# A64 register map
Vendor: Allwinner; Series: A64; File version: 0.1
CPU: CA53 0, little endian, MPU, no FPU, 0 interrupt priority bits
Registers are 32-bit, read-write, reset 0x0 unless marked. A register's access mark holds for its fields unless they carry their own. Offsets are from the block's base; [hi:lo] are bit positions; {n}, {i} and the like mark numbered series; 'fields as' and 'values as' point back to an identical list.

## PIO
Base 0x01C20800
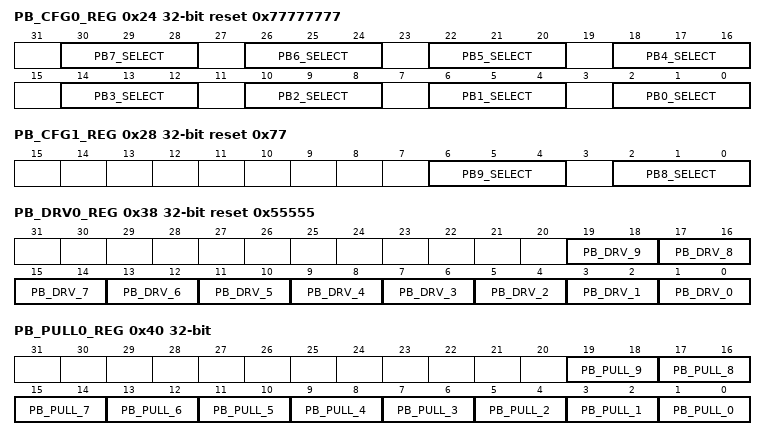
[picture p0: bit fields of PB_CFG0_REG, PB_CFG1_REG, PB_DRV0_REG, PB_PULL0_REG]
0x24 PB_CFG0_REG reset 0x77777777
  [30:28] PB7_SELECT — 000: Input 001: Output 010: AIF2_DIN 011: PCM0_DIN 100: Reserved 101: SIM_DET 110: PB_EINT7 111: IO Disable
    0=Input; 1=Output; 2=AIF2_DIN; 3=PCM0_DIN; 5=SIM_DET; 6=PB_EINT7; 7=IO (IO Disable)
  [26:24] PB6_SELECT — 000: Input 001: Output 010: AIF2_DOUT 011: PCM0_DOUT 100: Reserved 101: SIM_RST 110: PB_EINT6 111: IO Disable
    0=Input; 1=Output; 2=AIF2_DOUT; 3=PCM0_DOUT; 5=SIM_RST; 6=PB_EINT6; 7=IO (IO Disable)
  [22:20] PB5_SELECT — 000: Input 001: Output 010: AIF2_BCLK 011: PCM0_BCLK 100: Reserved 101: SIM_DATA 110: PB_EINT5 111: IO Disable
    0=Input; 1=Output; 2=AIF2_BCLK; 3=PCM0_BCLK; 5=SIM_DATA; 6=PB_EINT5; 7=IO (IO Disable)
  [18:16] PB4_SELECT — 000: Input 001: Output 010: AIF2_SYNC 011: PCM0_SYNC 100: Reserved 101: SIM_CLK 110: PB_EINT4 111: IO Disable
    0=Input; 1=Output; 2=AIF2_SYNC; 3=PCM0_SYNC; 5=SIM_CLK; 6=PB_EINT4; 7=IO (IO Disable)
  [14:12] PB3_SELECT — 000: Input 001: Output 010: UART2_CTS 011: I2S0_MCLK 100: JTAG_DI0 101: SIM_VPPPP 110: PB_EINT3 111: IO Disable
    0=Input; 1=Output; 2=UART2_CTS; 3=I2S0_MCLK; 4=JTAG_DI0; 5=SIM_VPPPP; 6=PB_EINT3; 7=IO (IO Disable)
  [10:8] PB2_SELECT — 000: Input 001: Output 010: UART2_RTS 011: Reserved 100: JTAG_DO0 101: SIM_VPPEN 110: PB_EINT2 111: IO Disable
    0=Input; 1=Output; 2=UART2_RTS; 4=JTAG_DO0; 5=SIM_VPPEN; 6=PB_EINT2; 7=IO (IO Disable)
  [6:4] PB1_SELECT — 000: Input 001: Output 010: UART2_RX 011: Reserved 100: JTAG_CK0 101: SIM_PWREN 110: PB_EINT1 111: IO Disable
    0=Input; 1=Output; 2=UART2_RX; 4=JTAG_CK0; 5=SIM_PWREN; 6=PB_EINT1; 7=IO (IO Disable)
  [2:0] PB0_SELECT — 000: Input 001: Output 010: UART2_TX 011: Reserved 100: JTAG_MS0 101: Reserved 110: PB_EINT0 111: IO Disable
    0=Input; 1=Output; 2=UART2_TX; 4=JTAG_MS0; 6=PB_EINT0; 7=IO (IO Disable)
0x28 PB_CFG1_REG reset 0x77
  [6:4] PB9_SELECT — 000: Input 001: Output 010: Reserved 011: Reserved 100: UART0_RX 101: Reserved 110: PB_EINT9 111: IO Disable
    0=Input; 1=Output; 4=UART0_RX; 6=PB_EINT9; 7=IO (IO Disable)
  [2:0] PB8_SELECT — 000: Input 001: Output 010: Reserved 011: Reserved 100: UART0_TX 101: Reserved 110: PB_EINT8 111: IO Disable
    0=Input; 1=Output; 4=UART0_TX; 6=PB_EINT8; 7=IO (IO Disable)
0x2C PB_CFG2_REG reset not defined
0x30 PB_CFG3_REG reset not defined
0x34 PB_DATA_REG
  [9:0] PB_DAT — If the port is configured as input, the corresponding bit is the pin state. If the port is configured as output, the pin state is the same as the corresponding bit. The read bit value is the value setup by software. If the port is configured as functional pin, the undefined value will be read.
0x38 PB_DRV0_REG reset 0x55555
  [2n+1:2n] PB_DRV_{n} (n=0..9) — PB[n] Multi-Driving Select (n = 0~9) 00: Level 0 01: Level 1 10: Level 2 11: Level 3
0x3C PB_DRV1_REG reset not defined
0x40 PB_PULL0_REG
  [2n+1:2n] PB_PULL_{n} (n=0..9) — PB[n] Pull-up/down Select (n = 0~9) 00: Pull-up/down disable 01: Pull-up 10: Pull-down 11: Reserved
0x44 PB_PULL1_REG reset not defined
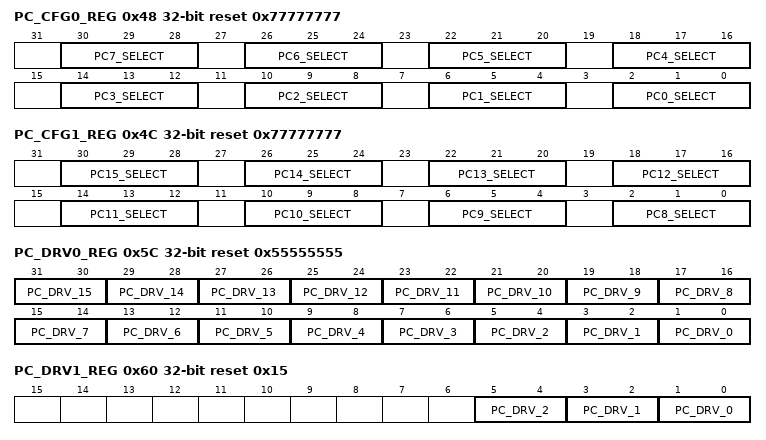
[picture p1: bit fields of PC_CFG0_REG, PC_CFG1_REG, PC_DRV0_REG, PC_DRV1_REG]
0x48 PC_CFG0_REG reset 0x77777777
  [30:28] PC7_SELECT — 000: Input 001: Output 010: NAND_RB1 011: Reserved 100: Reserved 101: Reserved 110: Reserved 111: IO Disable
    0=Input; 1=Output; 2=NAND_RB1; 7=IO (IO Disable)
  [26:24] PC6_SELECT — 000: Input 001: Output 010: NAND_RB0 011: SDC2_CMD 100: Reserved 101: Reserved 110: Reserved 111: IO Disable
    0=Input; 1=Output; 2=NAND_RB0; 3=SDC2_CMD; 7=IO (IO Disable)
  [22:20] PC5_SELECT — 000: Input 001: Output 010: NAND_RE 011: SDC2_CLK 100: Reserved 101: Reserved 110: Reserved 111: IO Disable
    0=Input; 1=Output; 2=NAND_RE; 3=SDC2_CLK; 7=IO (IO Disable)
  [18:16] PC4_SELECT — 000: Input 001: Output 010: NAND_CE0 011: Reserved 100: Reserved 101: Reserved 110: Reserved 111: IO Disable
    0=Input; 1=Output; 2=NAND_CE0; 7=IO (IO Disable)
  [14:12] PC3_SELECT — 000: Input 001: Output 010: NAND_CE1 011: Reserved 100: SPI0_CS 101: Reserved 110: Reserved 111: IO Disable
    0=Input; 1=Output; 2=NAND_CE1; 4=SPI0_CS; 7=IO (IO Disable)
  [10:8] PC2_SELECT — 000: Input 001: Output 010: NAND_CLE 011: Reserved 100: SPI0_CLK 101: Reserved 110: Reserved 111: IO Disable
    0=Input; 1=Output; 2=NAND_CLE; 4=SPI0_CLK; 7=IO (IO Disable)
  [6:4] PC1_SELECT — 000: Input 001: Output 010: NAND_ALE 011: SDC2_DS 100: SPI0_MISO 101: Reserved 110: Reserved 111: IO Disable
    0=Input; 1=Output; 2=NAND_ALE; 3=SDC2_DS; 4=SPI0_MISO; 7=IO (IO Disable)
  [2:0] PC0_SELECT — 000: Input 001: Output 010: NAND_WE 011: Reserved 100: SPI0_MOSI 101: Reserved 110: Reserved 111: IO Disable
    0=Input; 1=Output; 2=NAND_WE; 4=SPI0_MOSI; 7=IO (IO Disable)
0x4C PC_CFG1_REG reset 0x77777777
  [4n-30:4n-32] PC{n}_SELECT (n=8..15) — 000:Input 001:Output 010:NAND_DQ{n-8} 011:SDC2_D{n-8} 100:Reserved 101:Reserved 110:Reserved 111:IO Disable
0x50 PC_CFG2_REG reset 0x777
  [2:0] PC16_SELECT — 000:Input 001:Output 010:NAND_DQS 011:SDC2_RST 100:Reserved 101:Reserved 110:Reserved 111:IO Disable
0x54 PC_CFG3_REG reset not defined
0x58 PC_DATA_REG
  [18:0] PC_DAT — If the port is configured as input, the corresponding bit is the pin state. If the port is configured as output, the pin state is the same as the corresponding bit. The read bit value is the value setup by software. If the port is configured as functional pin, the undefined value will be read.
0x5C PC_DRV0_REG reset 0x55555555
  [2n+1:2n] PC_DRV_{n} (n=0..15) — PC[n] Multi-Driving SELECT (n = 0~15) 00: Level 0 01: Level 1 10: Level 2 11: Level 3
0x60 PC_DRV1_REG reset 0x15
  [5:4] PC_DRV_2 — PC[n] Multi-Driving Select (n = 16~18) 00: Level 0 01: Level 1 10: Level 2 11: Level 3
  [3:2] PC_DRV_1 — PC[n] Multi-Driving Select (n = 16~18) 00: Level 0 01: Level 1 10: Level 2 11: Level 3
  [1:0] PC_DRV_0 — PC[n] Multi-Driving Select (n = 16~18) 00: Level 0 01: Level 1 10: Level 2 11: Level 3
0x64 PC_PULL0_REG reset not defined
0x68 PC_PULL1_REG reset not defined
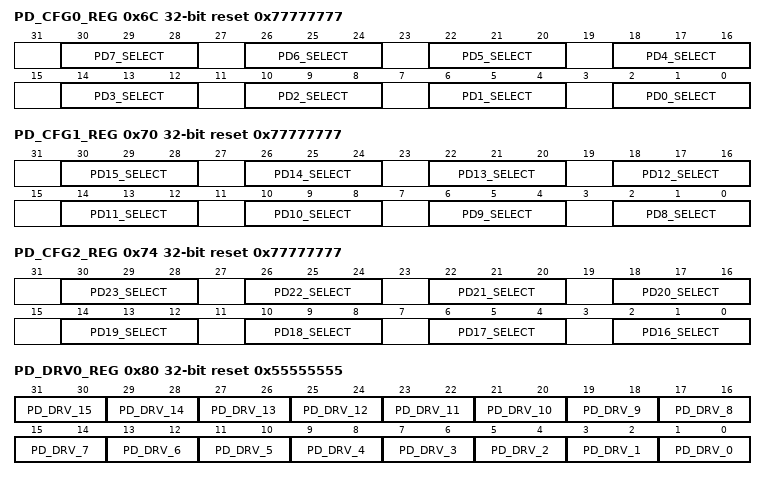
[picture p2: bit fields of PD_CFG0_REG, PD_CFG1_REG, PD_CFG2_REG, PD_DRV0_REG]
0x6C PD_CFG0_REG reset 0x77777777
  [30:28] PD7_SELECT — 000: Input 001: Output 010: LCD_D11 011: Reserved 100: Reserved 101: CCIR_D3 110: Reserved 111: IO Disable
    0=Input; 1=Output; 2=LCD_D11; 5=CCIR_D3; 7=IO (IO Disable)
  [26:24] PD6_SELECT — 000: Input 001: Output 010: LCD_D10 011: Reserved 100: Reserved 101: CCIR_D2 110: Reserved 111: IO Disable
    0=Input; 1=Output; 2=LCD_D10; 5=CCIR_D2; 7=IO (IO Disable)
  [22:20] PD5_SELECT — 000: Input 001: Output 010: LCD_D7 011: UART4_CTS 100: Reserved 101: CCIR_D1 110: Reserved 111: IO Disable
    0=Input; 1=Output; 2=LCD_D7; 3=UART4_CTS; 5=CCIR_D1; 7=IO (IO Disable)
  [18:16] PD4_SELECT — 000: Input 001: Output 010: LCD_D6 011: UART4_RTS 100: Reserved 101: CCIR_D0 110: Reserved 111: IO Disable
    0=Input; 1=Output; 2=LCD_D6; 3=UART4_RTS; 5=CCIR_D0; 7=IO (IO Disable)
  [14:12] PD3_SELECT — 000: Input 001: Output 010: LCD_D5 011: UART4_RX 100: SPI1_MISO 101: CCIR_VSYNC 110: Reserved 111: IO Disable
    0=Input; 1=Output; 2=LCD_D5; 3=UART4_RX; 4=SPI1_MISO; 5=CCIR_VSYNC; 7=IO (IO Disable)
  [10:8] PD2_SELECT — 000: Input 001: Output 010: LCD_D4 011: UART4_TX 100: SPI1_MOSI 101: CCIR_HSYNC 110: Reserved 111: IO Disable
    0=Input; 1=Output; 2=LCD_D4; 3=UART4_TX; 4=SPI1_MOSI; 5=CCIR_HSYNC; 7=IO (IO Disable)
  [6:4] PD1_SELECT — 000: Input 001: Output 010: LCD_D3 011: UART3_RX 100: SPI1_CLK 101: CCIR_DE 110: Reserved 111: IO Disable
    0=Input; 1=Output; 2=LCD_D3; 3=UART3_RX; 4=SPI1_CLK; 5=CCIR_DE; 7=IO (IO Disable)
  [2:0] PD0_SELECT — 000: Input 001: Output 010: LCD_D2 011: UART3_TX 100: SPI1_CS 101: CCIR_CLK 110: Reserved 111: IO Disable
    0=Input; 1=Output; 2=LCD_D2; 3=UART3_TX; 4=SPI1_CS; 5=CCIR_CLK; 7=IO (IO Disable)
0x70 PD_CFG1_REG reset 0x77777777
  [30:28] PD15_SELECT — 000: Input 001: Output 010: LCD_D21 011: LVDS_VN1 100: RGMII_TXD3/MII_TXD3/RMII_NULL 101: CCIR_D6 110: Reserved 111: IO Disable
    0=Input; 1=Output; 2=LCD_D21; 3=LVDS_VN1; 4=RGMII_TXD3_slash_MII_TXD3_slash_RMII_NULL (RGMII_TXD3/MII_TXD3/RMII_NULL 101: CCIR_D6); 7=IO (IO Disable)
  [26:24] PD14_SELECT — 000: Input 001: Output 010: LCD_D20 011: LVDS_VP1 100: RGMII_NULL/MII_RXERR/RMII_RXER 101: Reserved 110: Reserved 111: IO Disable
    0=Input; 1=Output; 2=LCD_D20; 3=LVDS_VP1; 4=RGMII_NULL_slash_MII_RXERR_slash_RMII_RXER (RGMII_NULL/MII_RXERR/RMII_RXER 101: Reserved); 7=IO (IO Disable)
  [22:20] PD13_SELECT — 000: Input 001: Output 010: LCD_D19 011: LVDS_VN0 100: RGMII_RXCTL / MII_RXDV/RMII_CRS_DV 101: Reserved 110: Reserved 111: IO Disable
    0=Input; 1=Output; 2=LCD_D19; 3=LVDS_VN0; 4=RGMII_RXCTL (RGMII_RXCTL / MII_RXDV/RMII_CRS_DV 101: Reserved); 7=IO (IO Disable)
  [18:16] PD12_SELECT — 000: Input 001: Output 010: LCD_D18 011: LVDS_VP0 100: RGMII_RXCK/MII_RXCK/RMII_NULL 101: Reserved 110: Reserved 111: IO Disable
    0=Input; 1=Output; 2=LCD_D18; 3=LVDS_VP0; 4=RGMII_RXCK_slash_MII_RXCK_slash_RMII_NULL (RGMII_RXCK/MII_RXCK/RMII_NULL 101: Reserved); 7=IO (IO Disable)
  [14:12] PD11_SELECT — 000: Input 001: Output 010: LCD_D15 011: Reserved 100: RGMII_RXD0 / MII_RXD0/RMII_RXD0 101: Reserved 110: Reserved 111: IO Disable
    0=Input; 1=Output; 2=LCD_D15; 4=RGMII_RXD0 (RGMII_RXD0 / MII_RXD0/RMII_RXD0 101: Reserved); 7=IO (IO Disable)
  [10:8] PD10_SELECT — 000: Input 001: Output 010: LCD_D14 011: Reserved 100: RGMII_RXD1 / MII_RXD1/RMII_RXD1 101: Reserved 110: Reserved 111: IO Disable
    0=Input; 1=Output; 2=LCD_D14; 4=RGMII_RXD1 (RGMII_RXD1 / MII_RXD1/RMII_RXD1 101: Reserved); 7=IO (IO Disable)
  [6:4] PD9_SELECT — 000: Input 001: Output 010: LCD_D13 011: Reserved 100: RGMII_RXD2 / MII_RXD2/RMII_NULL 101: CCIR_D5 110: Reserved 111: IO Disable
    0=Input; 1=Output; 2=LCD_D13; 4=RGMII_RXD2 (RGMII_RXD2 / MII_RXD2/RMII_NULL 101: CCIR_D5); 7=IO (IO Disable)
  [2:0] PD8_SELECT — 000: Input 001: Output 010: LCD_D12 011: Reserved 100: RGMII_RXD3 / MII_RXD3/RMII_NULL 101: CCIR_D4 110: Reserved 111: IO Disable
    0=Input; 1=Output; 2=LCD_D12; 4=RGMII_RXD3 (RGMII_RXD3 / MII_RXD3/RMII_NULL 101: CCIR_D4); 7=IO (IO Disable)
0x74 PD_CFG2_REG reset 0x77777777
  [30:28] PD23_SELECT — 000: Input 001: Output 010: Reserved 011: Reserved 100: MDIO 101: Reserved 110: Reserved 111: IO Disable
    0=Input; 1=Output; 4=MDIO; 7=IO (IO Disable)
  [26:24] PD22_SELECT — 000: Input 001: Output 010: PWM0 011: Reserved 100: MDC 101: Reserved 110: Reserved 111: IO Disable
    0=Input; 1=Output; 2=PWM0; 4=MDC; 7=IO (IO Disable)
  [22:20] PD21_SELECT — 000: Input 001: Output 010: LCD_VSYNC 011: LVDS_VN3 100: RGMII_CLKIN/MII_COL/RMII_NULL 101: Reserved 110: Reserved 111: IO Disable
    0=Input; 1=Output; 2=LCD_VSYNC; 3=LVDS_VN3; 4=RGMII_CLKIN_slash_MII_COL_slash_RMII_NULL (RGMII_CLKIN/MII_COL/RMII_NULL 101: Reserved); 7=IO (IO Disable)
  [18:16] PD20_SELECT — 000: Input 001: Output 010: LCD_HSYNC 011: LVDS_VP3 100: RGMII_TXCTL / MII_TXEN/RMII_TXEN 101: Reserved 110: Reserved 111: IO Disable
    0=Input; 1=Output; 2=LCD_HSYNC; 3=LVDS_VP3; 4=RGMII_TXCTL (RGMII_TXCTL / MII_TXEN/RMII_TXEN 101: Reserved); 7=IO (IO Disable)
  [14:12] PD19_SELECT — 000: Input 001: Output 010: LCD_DE 011: LVDS_VNC 100: RGMII_TXCK/MII_TXCK/RMII_TXCK 101: Reserved 110: Reserved 111: IO Disable
    0=Input; 1=Output; 2=LCD_DE; 3=LVDS_VNC; 4=RGMII_TXCK_slash_MII_TXCK_slash_RMII_TXCK (RGMII_TXCK/MII_TXCK/RMII_TXCK 101: Reserved); 7=IO (IO Disable)
  [10:8] PD18_SELECT — 000: Input 001: Output 010: LCD_CLK 011: LVDS_VPC 100: RGMII_TXD0 / MII_TXD0/RMII_TXD0 101: Reserved 110: Reserved 111: IO Disable
    0=Input; 1=Output; 2=LCD_CLK; 3=LVDS_VPC; 4=RGMII_TXD0 (RGMII_TXD0 / MII_TXD0/RMII_TXD0 101: Reserved); 7=IO (IO Disable)
  [6:4] PD17_SELECT — 000: Input 001: Output 010: LCD_D23 011: LVDS_VN2 100: RGMII_TXD1/MII_TXD1/RMII_TXD1 101: Reserved 110: Reserved 111: IO Disable
    0=Input; 1=Output; 2=LCD_D23; 3=LVDS_VN2; 4=RGMII_TXD1_slash_MII_TXD1_slash_RMII_TXD1 (RGMII_TXD1/MII_TXD1/RMII_TXD1 101: Reserved); 7=IO (IO Disable)
  [2:0] PD16_SELECT — 000: Input 001: Output 010: LCD_D22 011: LVDS_VP2 100: RGMII_TXD2/MII_TXD2/RMII_NULL 101: CCIR_D7 110: Reserved 111: IO Disable
    0=Input; 1=Output; 2=LCD_D22; 3=LVDS_VP2; 4=RGMII_TXD2_slash_MII_TXD2_slash_RMII_NULL (RGMII_TXD2/MII_TXD2/RMII_NULL 101: CCIR_D7); 7=IO (IO Disable)
0x78 PD_CFG3_REG reset 0x7
  [2:0] PD24_SELECT — 000: Input 001: Output 010: Reserved 011: Reserved 100: Reserved 101: Reserved 110: Reserved 111: IO Disable
    0=Input; 1=Output; 7=IO (IO Disable)
0x7C PD_DATA__REG
  [24:0] PD_DAT — If the port is configured as input, the corresponding bit is the pin state. If the port is configured as output, the pin state is the same as the corresponding bit. The read bit value is the value setup by software. If the port is configured as functional pin, the undefined value will be read.
0x80 PD_DRV0_REG reset 0x55555555
  [2n+1:2n] PD_DRV_{n} (n=0..15) — PD[n] Multi-Driving SELECT (n = 0~15) 00: Level 0 01: Level 1 10: Level 2 11: Level 3
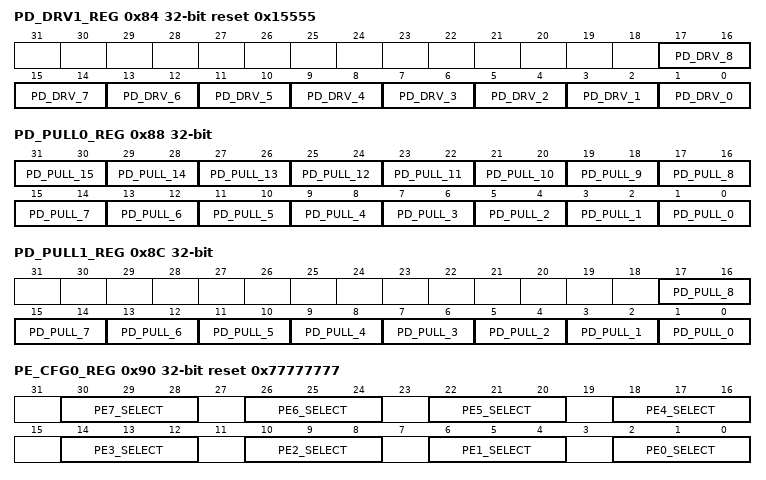
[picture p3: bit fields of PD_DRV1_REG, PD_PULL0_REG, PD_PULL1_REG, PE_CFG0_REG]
0x84 PD_DRV1_REG reset 0x15555
  [2n+1:2n] PD_DRV_{n} (n=0..8) — PD[n] Multi-Driving Select (n = 16~24) 00: Level 0 01: Level 1 10: Level 2 11: Level 3
0x88 PD_PULL0_REG
  [2n+1:2n] PD_PULL_{n} (n=0..15) — PD[n] Pull-up/down Select (n = 0~15) 00: Pull-up/down disable 01: Pull-up 10: Pull-down 11: Reserved
0x8C PD_PULL1_REG
  [2n+1:2n] PD_PULL_{n} (n=0..8) — PD[n] Pull-up/down Select (n = 16~24) 00: Pull-up/down disable 01: Pull-up 10: Pull-down 11: Reserved
0x90 PE_CFG0_REG reset 0x77777777
  [4n+2:4n] PE{n}_SELECT (n=4..7) — 000: Input 001: Output 010: CSI_D{n-4} 011: Reserved 100: TS_D{n-4} 101: Reserved 110: Reserved 111: IO Disable
    0=Input; 1=Output; 2=CSI_D{n-4}; 4=TS_D{n-4}; 7=IO (IO Disable)
  [14:12] PE3_SELECT — 000: Input 001: Output 010: CSI_VSYNC 011: Reserved 100: TS_DVLD 101: Reserved 110: Reserved 111: IO Disable
    0=Input; 1=Output; 2=CSI_VSYNC; 4=TS_DVLD; 7=IO (IO Disable)
  [10:8] PE2_SELECT — 000: Input 001: Output 010: CSI_HSYNC 011: Reserved 100: TS_SYNC 101: Reserved 110: Reserved 111: IO Disable
    0=Input; 1=Output; 2=CSI_HSYNC; 4=TS_SYNC; 7=IO (IO Disable)
  [6:4] PE1_SELECT — 000: Input 001: Output 010: CSI_MCLK 011: Reserved 100: TS_ERR 101: Reserved 110: Reserved 111: IO Disable
    0=Input; 1=Output; 2=CSI_MCLK; 4=TS_ERR; 7=IO (IO Disable)
  [2:0] PE0_SELECT — 000: Input 001: Output 010: CSI_PCLK 011: Reserved 100: TS_CLK 101: Reserved 110: Reserved 111: IO Disable
    0=Input; 1=Output; 2=CSI_PCLK; 4=TS_CLK; 7=IO (IO Disable)
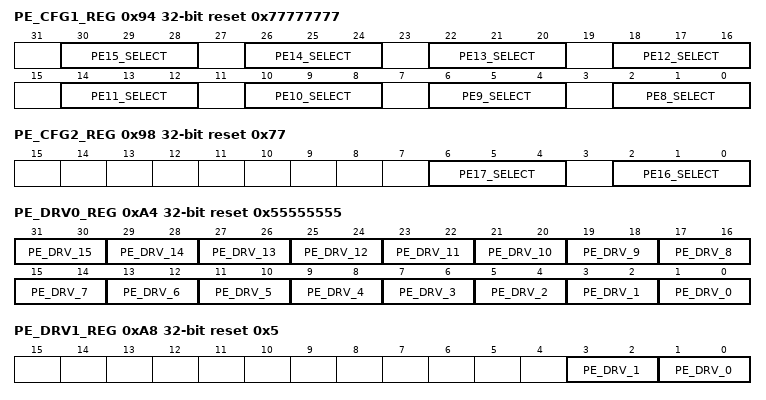
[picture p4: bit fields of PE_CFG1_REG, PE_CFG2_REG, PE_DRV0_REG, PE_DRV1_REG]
0x94 PE_CFG1_REG reset 0x77777777
  [30:28] PE15_SELECT — 000: Input 001: Output 010: Reserved 011: TWI2_SDA 100: Reserved 101: Reserved 110: Reserved 111: IO Disable
    0=Input; 1=Output; 3=TWI2_SDA; 7=IO (IO Disable)
  [26:24] PE14_SELECT — 000: Input 001: Output 010: PLL_LOCK_DBG 011: TWI2_SCK 100: Reserved 101: Reserved 110: Reserved 111: IO Disable
    0=Input; 1=Output; 2=PLL_LOCK_DBG; 3=TWI2_SCK; 7=IO (IO Disable)
  [22:20] PE13_SELECT — 000: Input 001: Output 010: CSI_SDA 011: Reserved 100: Reserved 101: Reserved 110: Reserved 111: IO Disable
    0=Input; 1=Output; 2=CSI_SDA; 7=IO (IO Disable)
  [18:16] PE12_SELECT — 000: Input 001: Output 010: CSI_SCK 011: Reserved 100: Reserved 101: Reserved 110: Reserved 111: IO Disable
    0=Input; 1=Output; 2=CSI_SCK; 7=IO (IO Disable)
  [4n-30:4n-32] PE{n}_SELECT (n=8..11) — 000: Input 001: Output 010: CSI_D{n-4} 011: Reserved 100: TS_D{n-4} 101: Reserved 110: Reserved 111: IO Disable
    values as PE_CFG0_REG.PE4_SELECT
0x98 PE_CFG2_REG reset 0x77
  [6:4] PE17_SELECT — 000: Input 001: Output 010: Reserved 011: Reserved 100: Reserved 101: Reserved 110: Reserved 111: IO Disable
    0=Input; 1=Output; 7=IO (IO Disable)
  [2:0] PE16_SELECT — 000: Input 001: Output 010: Reserved 011: Reserved 100: Reserved 101: Reserved 110: Reserved 111: IO Disable
    0=Input; 1=Output; 7=IO (IO Disable)
0x9C PE_CFG3_REG reset not defined
0xA0 PE_DATA__REG
  [17:0] PE_DAT — If the port is configured as input, the corresponding bit is the pin state. If the port is configured as output, the pin state is the same as the corresponding bit. The read bit value is the value setup by software. If the port is configured as functional pin, the undefined value will be read.
0xA4 PE_DRV0_REG reset 0x55555555
  [2n+1:2n] PE_DRV_{n} (n=0..15) — PE[n] Multi-Driving SELECT (n = 0~15) 00: Level 0 01: Level 1 10: Level 2 11: Level 3
0xA8 PE_DRV1_REG reset 0x5
  [3:2] PE_DRV_1 — PE[n] Multi-Driving Select (n = 16~17) 00: Level 0 01: Level 1 10: Level 2 11: Level 3
  [1:0] PE_DRV_0 — PE[n] Multi-Driving Select (n = 16~17) 00: Level 0 01: Level 1 10: Level 2 11: Level 3
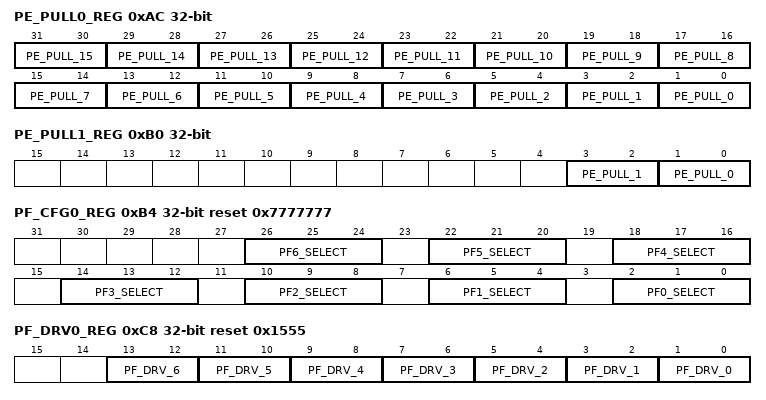
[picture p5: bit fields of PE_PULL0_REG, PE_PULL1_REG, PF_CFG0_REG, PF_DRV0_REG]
0xAC PE_PULL0_REG
  [2n+1:2n] PE_PULL_{n} (n=0..15) — PE[n] Pull-up/down Select (n = 0~15) 00: Pull-up/down disable 01: Pull-up 10: Pull-down 11: Reserved
0xB0 PE_PULL1_REG
  [3:2] PE_PULL_1 — PE[n] Pull-up/down Select (n = 16~17) 00: Pull-up/down disable 01: Pull-up 10: Pull-down 11: Reserved
  [1:0] PE_PULL_0 — PE[n] Pull-up/down Select (n = 16~17) 00: Pull-up/down disable 01: Pull-up 10: Pull-down 11: Reserved
0xB4 PF_CFG0_REG reset 0x7777777
  [26:24] PF6_SELECT — 000: Input 001: Output 010: Reserved 011: Reserved 100: Reserved 101: Reserved 110: Reserved 111: IO Disable
    0=Input; 1=Output; 7=IO (IO Disable)
  [22:20] PF5_SELECT — 000: Input 001: Output 010: SDC0_D2 011: JTAG_CK1 100: Reserved 101: Reserved 110: Reserved 111: IO Disable
    0=Input; 1=Output; 2=SDC0_D2; 3=JTAG_CK1; 7=IO (IO Disable)
  [18:16] PF4_SELECT — 000: Input 001: Output 010: SDC0_D3 011: UART0_RX 100: Reserved 101: Reserved 110: Reserved 111: IO Disable
    0=Input; 1=Output; 2=SDC0_D3; 3=UART0_RX; 7=IO (IO Disable)
  [14:12] PF3_SELECT — 000: Input 001: Output 010: SDC0_CMD 011: JTAG_DO1 100: Reserved 101: Reserved 110: Reserved 111: IO Disable
    0=Input; 1=Output; 2=SDC0_CMD; 3=JTAG_DO1; 7=IO (IO Disable)
  [10:8] PF2_SELECT — 000: Input 001: Output 010: SDC0_CLK 011: UART0_TX 100: Reserved 101: Reserved 110: Reserved 111: IO Disable
    0=Input; 1=Output; 2=SDC0_CLK; 3=UART0_TX; 7=IO (IO Disable)
  [6:4] PF1_SELECT — 000: Input 001: Output 010: SDC0_D0 011: JTAG_DI1 100: Reserved 101: Reserved 110: Reserved 111: IO Disable
    0=Input; 1=Output; 2=SDC0_D0; 3=JTAG_DI1; 7=IO (IO Disable)
  [2:0] PF0_SELECT — 000: Input 001: Output 010: SDC0_D1 011: JTAG_MS1 100: Reserved 101: Reserved 110: Reserved 111: IO Disable
    0=Input; 1=Output; 2=SDC0_D1; 3=JTAG_MS1; 7=IO (IO Disable)
{0xB4+4i} PF_CFG{i}_REG reset not defined (i=1..3)
0xC4 PF_DATA_REG
  [6:0] PF_DAT — If the port is configured as input, the corresponding bit is the pin state. If the port is configured as output, the pin state is the same as the corresponding bit. The read bit value is the value setup by software. If the port is configured as functional pin, the undefined value will be read.
0xC8 PF_DRV0_REG reset 0x1555
  [2n+1:2n] PF_DRV_{n} (n=0..6) — PF[n] Multi-Driving SELECT (n = 0~6) 00: Level 0 01: Level 1 10: Level 2 11: Level 3
0xCC PF_DRV1_REG reset not defined
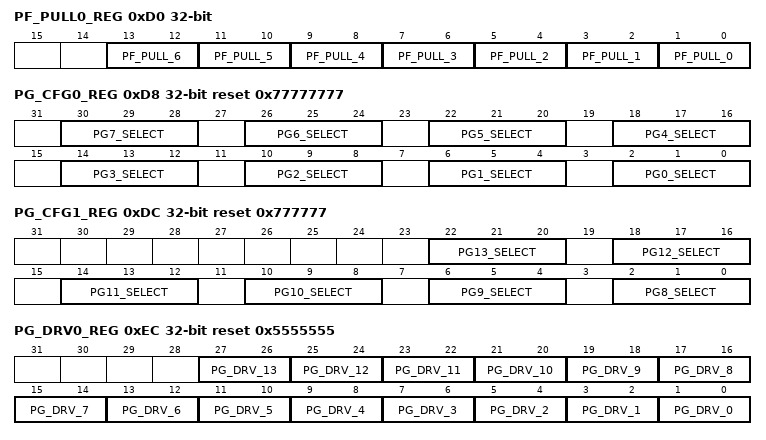
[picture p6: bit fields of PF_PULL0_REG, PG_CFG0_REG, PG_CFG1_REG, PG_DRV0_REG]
0xD0 PF_PULL0_REG
  [2n+1:2n] PF_PULL_{n} (n=0..6) — PF[n] Pull-up/down Select (n = 0~6) 00: Pull-up/down disable 01: Pull-up 10: Pull-down 11: Reserved
0xD4 PF_PULL1_REG reset not defined
0xD8 PG_CFG0_REG reset 0x77777777
  [30:28] PG7_SELECT — 000: Input 001: Output 010: UART1_RX 011: Reserved 100: Reserved 101: Reserved 110: PG_EINT7 111: IO Disable
    0=Input; 1=Output; 2=UART1_RX; 6=PG_EINT7; 7=IO (IO Disable)
  [26:24] PG6_SELECT — 000: Input 001: Output 010: UART1_TX 011: Reserved 100: Reserved 101: Reserved 110: PG_EINT6 111: IO Disable
    0=Input; 1=Output; 2=UART1_TX; 6=PG_EINT6; 7=IO (IO Disable)
  [4n+2:4n] PG{n}_SELECT (n=2..5) — 000: Input 001: Output 010: SDC1_D{n-2} 011: Reserved 100: Reserved 101: Reserved 110: PG_EINT{n} 111: IO Disable
    0=Input; 1=Output; 2=SDC1_D{n-2}; 6=PG_EINT{n}; 7=IO (IO Disable)
  [6:4] PG1_SELECT — 000: Input 001: Output 010: SDC1_CMD 011: Reserved 100: Reserved 101: Reserved 110: PG_EINT1 111: IO Disable
    0=Input; 1=Output; 2=SDC1_CMD; 6=PG_EINT1; 7=IO (IO Disable)
  [2:0] PG0_SELECT — 000: Input 001: Output 010: SDC1_CLK 011: Reserved 100: Reserved 101: Reserved 110: PG_EINT0 111: IO Disable
    0=Input; 1=Output; 2=SDC1_CLK; 6=PG_EINT0; 7=IO (IO Disable)
0xDC PG_CFG1_REG reset 0x777777
  [22:20] PG13_SELECT — 000: Input 001: Output 010: AIF3_DIN 011: PCM1_DIN 100: Reserved 101: Reserved 110: PG_EINT13 111: IO Disable
    0=Input; 1=Output; 2=AIF3_DIN; 3=PCM1_DIN; 6=PG_EINT13; 7=IO (IO Disable)
  [18:16] PG12_SELECT — 000: Input 001: Output 010: AIF3_DOUT 011: PCM1_DOUT 100: Reserved 101: Reserved 110: PG_EINT12 111: IO Disable
    0=Input; 1=Output; 2=AIF3_DOUT; 3=PCM1_DOUT; 6=PG_EINT12; 7=IO (IO Disable)
  [14:12] PG11_SELECT — 000: Input 001: Output 010: AIF3_BCLK 011: PCM1_BCLK 100: Reserved 101: Reserved 110: PG_EINT11 111: IO Disable
    0=Input; 1=Output; 2=AIF3_BCLK; 3=PCM1_BCLK; 6=PG_EINT11; 7=IO (IO Disable)
  [10:8] PG10_SELECT — 000: Input 001: Output 010: AIF3_SYNC 011: PCM1_SYNC 100: Reserved 101: Reserved 110: PG_EINT10 111: IO Disable
    0=Input; 1=Output; 2=AIF3_SYNC; 3=PCM1_SYNC; 6=PG_EINT10; 7=IO (IO Disable)
  [6:4] PG9_SELECT — 000: Input 001: Output 010: UART1_CTS 011: Reserved 100: Reserved 101: Reserved 110: PG_EINT9 111: IO Disable
    0=Input; 1=Output; 2=UART1_CTS; 6=PG_EINT9; 7=IO (IO Disable)
  [2:0] PG8_SELECT — 000: Input 001: Output 010: UART1_RTS 011: Reserved 100: Reserved 101: Reserved 110: PG_EINT8 111: IO Disable
    0=Input; 1=Output; 2=UART1_RTS; 6=PG_EINT8; 7=IO (IO Disable)
0xE0 PG_CFG2_REG reset not defined
0xE4 PG_CFG3_REG reset not defined
0xE8 PG_DATA_REG
  [13:0] PG_DAT — If the port is configured as input, the corresponding bit is the pin state. If the port is configured as output, the pin state is the same as the corresponding bit. The read bit value is the value setup by software. If the port is configured as functional pin, the undefined value will be read.
0xEC PG_DRV0_REG reset 0x5555555
  [2n+1:2n] PG_DRV_{n} (n=0..13) — PG[n] Multi-Driving SELECT (n = 0~13) 00: Level 0 01: Level 1 10: Level 2 11: Level 3
0xF0 PG_DRV1_REG reset not defined
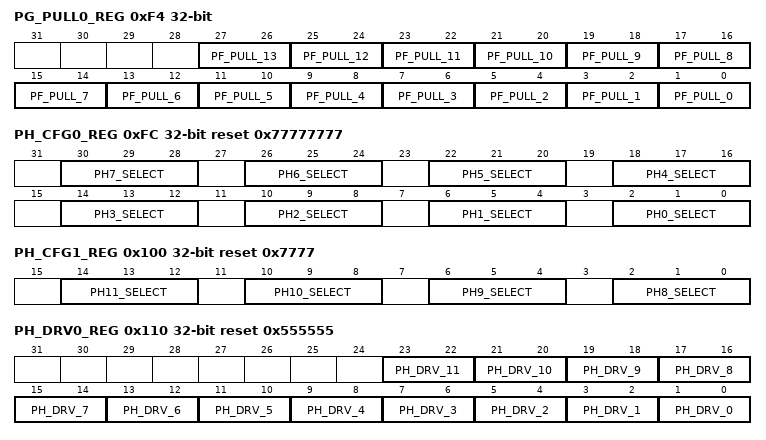
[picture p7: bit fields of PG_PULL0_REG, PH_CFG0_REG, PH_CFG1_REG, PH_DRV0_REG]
0xF4 PG_PULL0_REG
  [2n+1:2n] PF_PULL_{n} (n=0..13) — PF[n] Pull-up/down Select (n = 0~13) 00: Pull-up/down disable 01: Pull-up 10: Pull-down 11: Reserved
0xF8 PG_PULL1_REG reset not defined
0xFC PH_CFG0_REG reset 0x77777777
  [30:28] PH7_SELECT — 000: Input 001: Output 010: UART3_CTS 011: Reserved 100: Reserved 101: Reserved 110: PH_EINT7 111: IO Disable
    0=Input; 1=Output; 2=UART3_CTS; 6=PH_EINT7; 7=IO (IO Disable)
  [26:24] PH6_SELECT — 000: Input 001: Output 010: UART3_RTS 011: Reserved 100: Reserved 101: Reserved 110: PH_EINT6 111: IO Disable
    0=Input; 1=Output; 2=UART3_RTS; 6=PH_EINT6; 7=IO (IO Disable)
  [22:20] PH5_SELECT — 000: Input 001: Output 010: UART3_RX 011: Reserved 100: Reserved 101: Reserved 110: PH_EINT5 111: IO Disable
    0=Input; 1=Output; 2=UART3_RX; 6=PH_EINT5; 7=IO (IO Disable)
  [18:16] PH4_SELECT — 000: Input 001: Output 010: UART3_TX 011: Reserved 100: Reserved 101: Reserved 110: PH_EINT4 111: IO Disable
    0=Input; 1=Output; 2=UART3_TX; 6=PH_EINT4; 7=IO (IO Disable)
  [14:12] PH3_SELECT — 000: Input 001: Output 010: TWI1_SDA 011: Reserved 100: Reserved 101: Reserved 110: PH_EINT3 111: IO Disable
    0=Input; 1=Output; 2=TWI1_SDA; 6=PH_EINT3; 7=IO (IO Disable)
  [10:8] PH2_SELECT — 000: Input 001: Output 010: TWI1_SCK 011: Reserved 100: Reserved 101: Reserved 110: PH_EINT2 111: IO Disable
    0=Input; 1=Output; 2=TWI1_SCK; 6=PH_EINT2; 7=IO (IO Disable)
  [6:4] PH1_SELECT — 000: Input 001: Output 010: TWI0_SDA 011: Reserved 100: Reserved 101: Reserved 110: PH_EINT1 111: IO Disable
    0=Input; 1=Output; 2=TWI0_SDA; 6=PH_EINT1; 7=IO (IO Disable)
  [2:0] PH0_SELECT — 000: Input 001: Output 010: TWI0_SCK 011: Reserved 100: Reserved 101: Reserved 110: PH_EINT0 111: IO Disable
    0=Input; 1=Output; 2=TWI0_SCK; 6=PH_EINT0; 7=IO (IO Disable)
0x100 PH_CFG1_REG reset 0x7777
  [14:12] PH11_SELECT — 000: Input 001: Output 010: MIC_DATA 011: Reserved 100: Reserved 101: Reserved 110: PH_EINT11 111: IO Disable
    0=Input; 1=Output; 2=MIC_DATA; 6=PH_EINT11; 7=IO (IO Disable)
  [10:8] PH10_SELECT — 000: Input 001: Output 010: MIC_CLK 011: Reserved 100: Reserved 101: Reserved 110: PH_EINT10 111: IO Disable
    0=Input; 1=Output; 2=MIC_CLK; 6=PH_EINT10; 7=IO (IO Disable)
  [6:4] PH9_SELECT — 000: Input 001: Output 010: Reserved 011: Reserved 100: Reserved 101: Reserved 110: PH_EINT9 111: IO Disable
    0=Input; 1=Output; 6=PH_EINT9; 7=IO (IO Disable)
  [2:0] PH8_SELECT — 000: Input 001: Output 010: OWA_OUT 011: Reserved 100: Reserved 101: Reserved 110: PH_EINT8 111: IO Disable
    0=Input; 1=Output; 2=OWA_OUT; 6=PH_EINT8; 7=IO (IO Disable)
0x104 PH_CFG2_REG reset not defined
0x108 PH_CFG3_REG reset not defined
0x10C PH_DATA_REG
  [11:0] PH_DAT — If the port is configured as input, the corresponding bit is the pin state. If the port is configured as output, the pin state is the same as the correspondin
0x110 PH_DRV0_REG reset 0x555555
  [2n+1:2n] PH_DRV_{n} (n=0..11) — PH[n] Multi-Driving Select (n = 0~11) 00: Level 0 01: Level 1 10: Level 2 11: Level 3
0x114 PH_DRV1_REG reset not defined
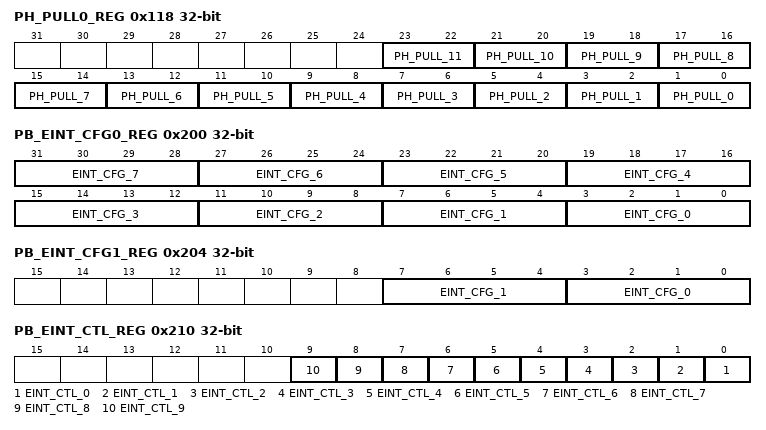
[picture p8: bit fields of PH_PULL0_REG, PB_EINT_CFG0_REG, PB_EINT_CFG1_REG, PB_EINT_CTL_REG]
0x118 PH_PULL0_REG
  [2n+1:2n] PH_PULL_{n} (n=0..11) — PH[n] Pull-up/down Select (n = 0~11) 00: Pull-up/down disable 01: Pull-up 10: Pull-down 11: Reserved
0x11C PH_PULL1_REG reset not defined
0x200 PB_EINT_CFG0_REG
  [4n+3:4n] EINT_CFG_{n} (n=0..7) — External INTn Mode (n = 0~7) 0x0: Positive Edge 0x1: Negative Edge 0x2: High Level 0x3: Low Level 0x4: Double Edge (Positive/ Negative) Others: Reserved
0x204 PB_EINT_CFG1_REG
  [7:4] EINT_CFG_1 — External INTn Mode (n = 8~9) 0x0: Positive Edge 0x1: Negative Edge 0x2: High Level 0x3: Low Level 0x4: Double Edge (Positive/ Negative) Others: Reserved
  [3:0] EINT_CFG_0 — External INTn Mode (n = 8~9) 0x0: Positive Edge 0x1: Negative Edge 0x2: High Level 0x3: Low Level 0x4: Double Edge (Positive/ Negative) Others: Reserved
0x208 PB_EINT_CFG2_REG reset not defined
0x20C PB_EINT_CFG3_REG reset not defined
0x210 PB_EINT_CTL_REG
  [n] EINT_CTL_{n} (n=0..9) — External INTn Enable (n = 0~9) 0: Disable 1: Enable
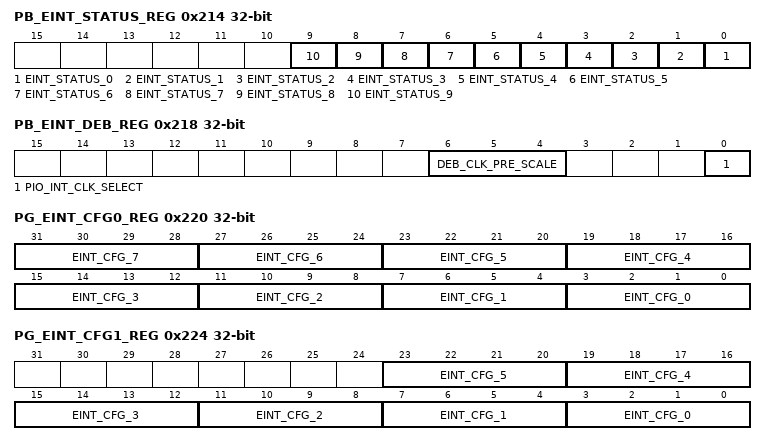
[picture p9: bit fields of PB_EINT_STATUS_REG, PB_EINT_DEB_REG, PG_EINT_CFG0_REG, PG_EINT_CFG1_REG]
0x214 PB_EINT_STATUS_REG
  [n] EINT_STATUS_{n} (n=0..9) — External INTn Pending Bit (n = 0~9) 0: No IRQ pending 1: IRQ pending Write `1` to clear
0x218 PB_EINT_DEB_REG
  [6:4] DEB_CLK_PRE_SCALE — Debounce Clock Pre-scale n The selected clock source is prescaled by 2^n.
  [0] PIO_INT_CLK_SELECT — PIO Interrupt Clock Select 0: LOSC 32Khz 1: HOSC 24Mhz
    0=LOSC (LOSC 32Khz); 1=HOSC (HOSC 24Mhz)
0x220 PG_EINT_CFG0_REG
  fields as PB_EINT_CFG0_REG
0x224 PG_EINT_CFG1_REG
  [4n+3:4n] EINT_CFG_{n} (n=0..5) — External INTn Mode (n = 8~13) 0x0: Positive Edge 0x1: Negative Edge 0x2: High Level 0x3: Low Level 0x4: Double Edge (Positive/ Negative) Others: Reserved
0x228 PG_EINT_CFG2_REG reset not defined
0x22C PG_EINT_CFG3_REG reset not defined
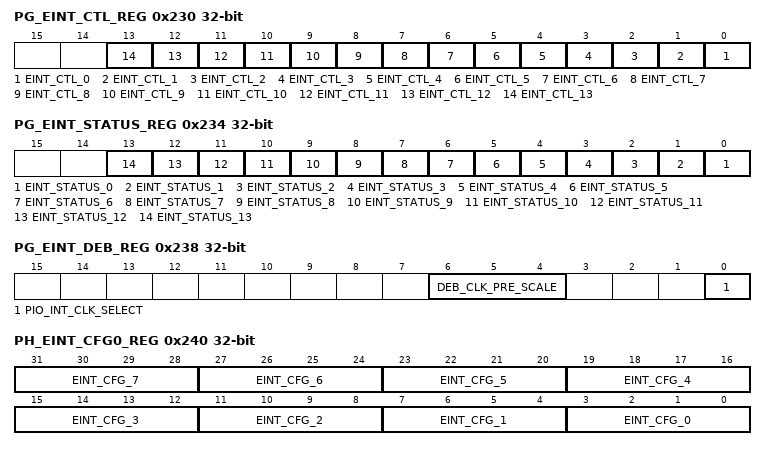
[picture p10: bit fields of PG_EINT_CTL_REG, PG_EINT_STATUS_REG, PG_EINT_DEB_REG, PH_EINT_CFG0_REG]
0x230 PG_EINT_CTL_REG
  [n] EINT_CTL_{n} (n=0..13) — External INTn Enable (n = 0~13) 0: Disable 1: Enable
0x234 PG_EINT_STATUS_REG
  [n] EINT_STATUS_{n} (n=0..13) — External INTn Pending Bit (n = 0~13) 0: No IRQ pending 1: IRQ pending Write `1` to clear
0x238 PG_EINT_DEB_REG
  fields as PB_EINT_DEB_REG
0x240 PH_EINT_CFG0_REG
  fields as PB_EINT_CFG0_REG
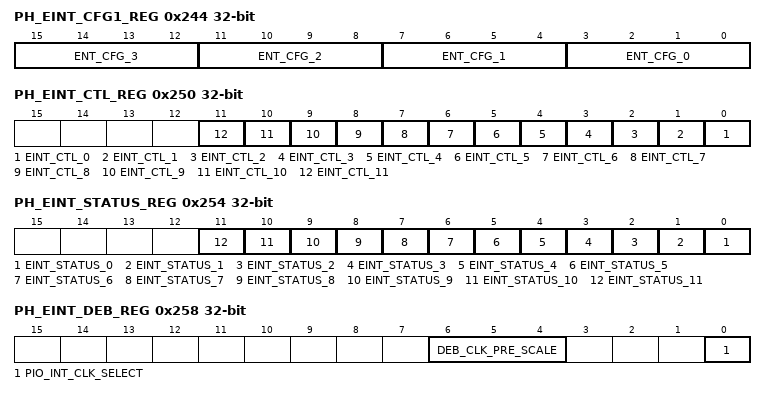
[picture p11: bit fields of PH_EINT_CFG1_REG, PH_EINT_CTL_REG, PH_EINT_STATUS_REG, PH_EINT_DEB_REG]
0x244 PH_EINT_CFG1_REG
  [4n+3:4n] ENT_CFG_{n} (n=0..3) — External INTn Mode (n = 8~11) 0x0: Positive Edge 0x1: Negative Edge 0x2: High Level 0x3: Low Level 0x4: Double Edge (Positive/ Negative) Others: Reserved
0x248 PH_EINT_CFG2_REG reset not defined
0x24C PH_EINT_CFG3_REG reset not defined
0x250 PH_EINT_CTL_REG
  [n] EINT_CTL_{n} (n=0..11) — External INTn Enable (n = 0~11) 0: Disable 1: Enable
0x254 PH_EINT_STATUS_REG
  [n] EINT_STATUS_{n} (n=0..11) — External INTn Pending Bit (n = 0~11) 0: No IRQ pending 1: IRQ pending Write `1` to clear
0x258 PH_EINT_DEB_REG
  fields as PB_EINT_DEB_REG
